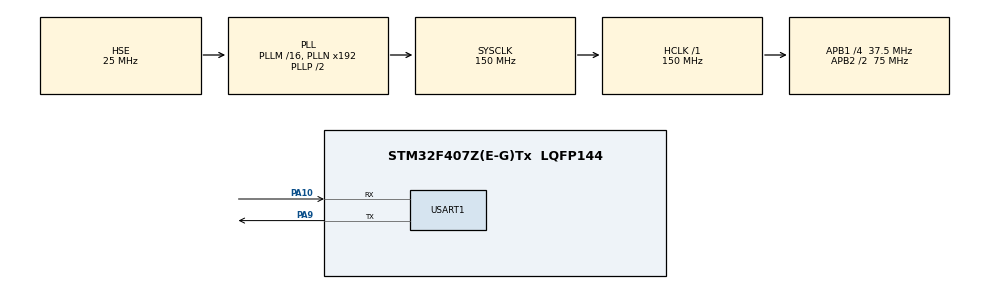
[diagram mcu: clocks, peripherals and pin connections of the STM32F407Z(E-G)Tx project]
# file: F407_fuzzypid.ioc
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Mcu.Family=STM32F4
Mcu.Name=STM32F407Z(E-G)Tx
Mcu.Package=LQFP144
NVIC.PriorityGroup=NVIC_PRIORITYGROUP_4
PA10.Mode=Asynchronous
PA10.Signal=USART1_RX
PA13.Mode=Serial_Wire
PA13.Signal=SYS_JTMS-SWDIO
PA14.Mode=Serial_Wire
PA14.Signal=SYS_JTCK-SWCLK
PA9.Mode=Asynchronous
PA9.Signal=USART1_TX
PH0-OSC_IN.Mode=HSE-External-Oscillator
PH0-OSC_IN.Signal=RCC_OSC_IN
PH1-OSC_OUT.Mode=HSE-External-Oscillator
PH1-OSC_OUT.Signal=RCC_OSC_OUT
ProjectManager.HeapSize=0x200
ProjectManager.StackSize=0x400
ProjectManager.TargetToolchain=MDK-ARM V5.32
RCC.48MHZClocksFreq_Value=75000000
RCC.AHBFreq_Value=150000000
RCC.APB1CLKDivider=RCC_HCLK_DIV4
RCC.APB1Freq_Value=37500000
RCC.APB1TimFreq_Value=75000000
RCC.APB2CLKDivider=RCC_HCLK_DIV2
RCC.APB2Freq_Value=75000000
RCC.APB2TimFreq_Value=150000000
RCC.CortexFreq_Value=150000000
RCC.HCLKFreq_Value=150000000
RCC.HSE_VALUE=25000000
RCC.HSI_VALUE=16000000
RCC.LSE_VALUE=32768
RCC.PLLSourceVirtual=RCC_PLLSOURCE_HSE
RCC.SYSCLKFreq_VALUE=150000000
RCC.SYSCLKSource=RCC_SYSCLKSOURCE_PLLCLK
RCC.VCOOutputFreq_Value=300000000
USART1.VirtualMode=VM_ASYNC
board=custom

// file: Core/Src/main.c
/* USER CODE BEGIN Header */
/**
  ******************************************************************************
  * @file           : main.c
  * @brief          : Main program body
  ******************************************************************************
  * @attention
  *
  * Copyright (c) 2025 STMicroelectronics.
  * All rights reserved.
  *
  * This software is licensed under terms that can be found in the LICENSE file
  * in the root directory of this software component.
  * If no LICENSE file comes with this software, it is provided AS-IS.
  *
  ******************************************************************************
  */
/* USER CODE END Header */
#include "main.h"
#include "usart.h"
#include "gpio.h"
#include "fuzzyPID.h"

/* USER CODE BEGIN PD */
#define DOF 6
/* USER CODE END PD */

void SystemClock_Config(void);

/* USER CODE BEGIN 0 */
int fputc(int ch, FILE *f)
  {
    uint8_t temp[1] = {ch};
    HAL_UART_Transmit(&huart1, temp, 1, 2);
    return ch;
  }
/* USER CODE END 0 */

int main(void)
{

  /* MCU Configuration--------------------------------------------------------*/

  /* Reset of all peripherals, Initializes the Flash interface and the Systick. */
  HAL_Init();

  /* Configure the system clock */
  SystemClock_Config();

  /* Initialize all configured peripherals */
  MX_GPIO_Init();
  MX_USART1_UART_Init();
  /* USER CODE BEGIN 2 */
  // Default fuzzy rule base of delta kp/ki/kd
    int rule_base[][qf_default] = {
            //delta kp rule base
            {PB, PB, PM, PM, PS, ZO, ZO},
            {PB, PB, PM, PS, PS, ZO, NS},
            {PM, PM, PM, PS, ZO, NS, NS},
            {PM, PM, PS, ZO, NS, NM, NM},
            {PS, PS, ZO, NS, NS, NM, NM},
            {PS, ZO, NS, NM, NM, NM, NB},
            {ZO, ZO, NM, NM, NM, NB, NB},
            //delta ki rule base
            {NB, NB, NM, NM, NS, ZO, ZO},
            {NB, NB, NM, NS, NS, ZO, ZO},
            {NB, NM, NS, NS, ZO, PS, PS},
            {NM, NM, NS, ZO, PS, PM, PM},
            {NM, NS, ZO, PS, PS, PM, PB},
            {ZO, ZO, PS, PS, PM, PB, PB},
            {ZO, ZO, PS, PM, PM, PB, PB},
            //delta kd rule base
            {PS, NS, NB, NB, NB, NM, PS},
            {PS, NS, NB, NM, NM, NS, ZO},
            {ZO, NS, NM, NM, NS, NS, ZO},
            {ZO, NS, NS, NS, NS, NS, ZO},
            {ZO, ZO, ZO, ZO, ZO, ZO, ZO},
            {PB, PS, PS, PS, PS, PS, PB},
            {PB, PM, PM, PM, PS, PS, PB}};

    // Default parameters of membership function
    int mf_params[4 * qf_default] = {-3, -3, -2, 0,
                                     -3, -2, -1, 0,
                                     -2, -1,  0, 0,
                                     -1,  0,  1, 0,
                                      0,  1,  2, 0,
                                      1,  2,  3, 0,
                                      2,  3,  3, 0};

    // Default parameters of pid controller
    float fuzzy_pid_params[DOF][pid_params_count] = {{0.65f,  0,     0,    0, 0, 0, 1},
                                                     {-0.34f, 0,     0,    0, 0, 0, 1},
                                                     {-1.1f,  0,     0,    0, 0, 0, 1},
                                                     {-2.4f,  0,     0,    0, 0, 0, 1},
                                                     {1.2f,   0,     0,    0, 0, 0, 1},
                                                     {1.2f,   0.05f, 0.1f, 0, 0, 0, 1}};

    // Obtain the PID controller vector according to the parameters
    struct PID **pid_vector = fuzzy_pid_vector_init(fuzzy_pid_params, 2.0f, 4, 1, 0, mf_params, rule_base, DOF);

    printf("output:\n");
    int control_id = 5;
    float real = 0;
    float idea = max_error * 0.9f;
    printf("idea value: %f\n", idea);
    bool direct[DOF] = {true, false, false, false, true, true};
  /* USER CODE END 2 */

  /* Infinite loop */
  /* USER CODE BEGIN WHILE */
  // while (1)
  // {
    /* USER CODE END WHILE */
    /* USER CODE BEGIN 3 */
    for (int j = 0; j < 1000; ++j) {
        int out = fuzzy_pid_motor_pwd_output(real, idea, direct[control_id], pid_vector[control_id]);
        real += (float) (out - middle_pwm_output) / (float) middle_pwm_output * (float) max_error * 0.1f;
        printf("%d,%f\n", out, real);
        // delay_ms(200);
    }
    // delete_pid_vector(pid_vector, DOF);

  //   return 0;
  // }
  /* USER CODE END 3 */
}

void SystemClock_Config(void)
{
  RCC_OscInitTypeDef RCC_OscInitStruct = {0};
  RCC_ClkInitTypeDef RCC_ClkInitStruct = {0};

  /** Configure the main internal regulator output voltage
  */
  __HAL_RCC_PWR_CLK_ENABLE();
  __HAL_PWR_VOLTAGESCALING_CONFIG(PWR_REGULATOR_VOLTAGE_SCALE1);

  /** Initializes the RCC Oscillators according to the specified parameters
  * in the RCC_OscInitTypeDef structure.
  */
  RCC_OscInitStruct.OscillatorType = RCC_OSCILLATORTYPE_HSE;
  RCC_OscInitStruct.HSEState = RCC_HSE_ON;
  RCC_OscInitStruct.PLL.PLLState = RCC_PLL_ON;
  RCC_OscInitStruct.PLL.PLLSource = RCC_PLLSOURCE_HSE;
  RCC_OscInitStruct.PLL.PLLM = 16;
  RCC_OscInitStruct.PLL.PLLN = 192;
  RCC_OscInitStruct.PLL.PLLP = RCC_PLLP_DIV2;
  RCC_OscInitStruct.PLL.PLLQ = 4;
  if (HAL_RCC_OscConfig(&RCC_OscInitStruct) != HAL_OK)
  {
    Error_Handler();
  }

  /** Initializes the CPU, AHB and APB buses clocks
  */
  RCC_ClkInitStruct.ClockType = RCC_CLOCKTYPE_HCLK|RCC_CLOCKTYPE_SYSCLK
                              |RCC_CLOCKTYPE_PCLK1|RCC_CLOCKTYPE_PCLK2;
  RCC_ClkInitStruct.SYSCLKSource = RCC_SYSCLKSOURCE_PLLCLK;
  RCC_ClkInitStruct.AHBCLKDivider = RCC_SYSCLK_DIV1;
  RCC_ClkInitStruct.APB1CLKDivider = RCC_HCLK_DIV4;
  RCC_ClkInitStruct.APB2CLKDivider = RCC_HCLK_DIV2;

  if (HAL_RCC_ClockConfig(&RCC_ClkInitStruct, FLASH_LATENCY_4) != HAL_OK)
  {
    Error_Handler();
  }
}

void Error_Handler(void)
{
  __disable_irq();
  while (1)
  {
  }
}
